# R7KA8D2AD register map
Vendor: Renesas Electronics Corporation; Series: RA8; File version: 1.10.02
CPU: CM85 r0p2, little endian, MPU, FPU, VTOR, 4 interrupt priority bits, 96 interrupts
Registers are 32-bit, read-write, reset 0x0 unless marked. A register's access mark holds for its fields unless they carry their own. Offsets are from the block's base; [hi:lo] are bit positions; {n}, {i} and the like mark numbered series; 'fields as' and 'values as' point back to an identical list.

## MRAM_NS — MS_NS System Register area
Base 0x5013C000
0x00 MRCPFB 8-bit — Code MRAM Prefetch Buffer Enable Register
  [0] MPFBEN — Code MRAM Prefetch Buffer Enable
    0=Prefetch buffer disable; 1=Prefetch buffer enable
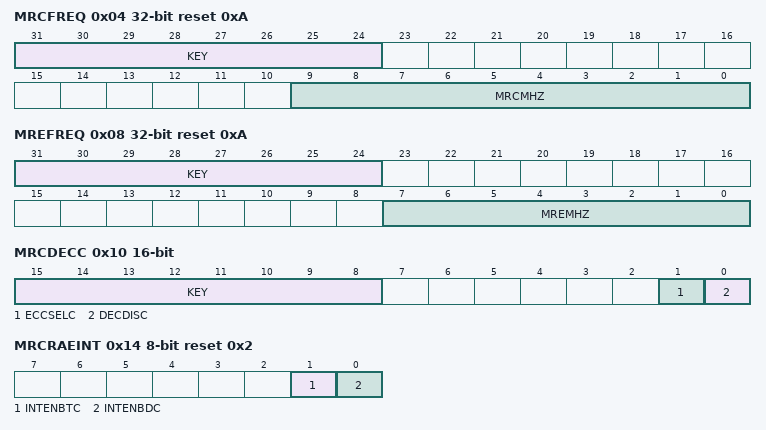
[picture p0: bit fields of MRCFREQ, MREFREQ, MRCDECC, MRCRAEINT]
0x04 MRCFREQ reset 0xA — Code MRAM Frequency Notifications Register
  [31:24] KEY — Key Code
  [9:0] MRCMHZ — Code MRAM Frequency Notifications
0x08 MREFREQ reset 0xA — Extra MRAM Frequency Notifications Register
  [31:24] KEY
  [7:0] MREMHZ — Extra MRAM Frequency Notifications
0x10 MRCDECC 16-bit — Code MRAM ECC Decoder Control Register
  [15:8] KEY — Key Code
  [1] ECCSELC — Code MRAM ECC Bits Select
    0=ECC bits unselect; 1=ECC bits select
  [0] DECDISC — Code MRAM ECC Decoder Disable
    0=ECC decoder enable; 1=ECC decoder disable
0x14 MRCRAEINT 8-bit reset 0x2 — Code MRAM Read Access Error Interrupt Enable Register
  [1] INTENBTC — Code MRAM TED Error Interrupt Enable
    0=Generation of an MRAM_MRCRD interrupt request is disabled when MRCRAES.TEDERRC is set to 1; 1=Generation of an MRAM_MRCRD interrupt request is enabled when MRCRAES.TEDERRC is set to 1
  [0] INTENBDC — Code MRAM DEC Error Interrupt Enable
    0=Generation of an MRAM_MRCRD interrupt request is disabled when MRCRAES.DECERRC is set to 1; 1=Generation of an MRAM_MRCRD interrupt request is enabled when MRCRAES.DECERRC is set to 1
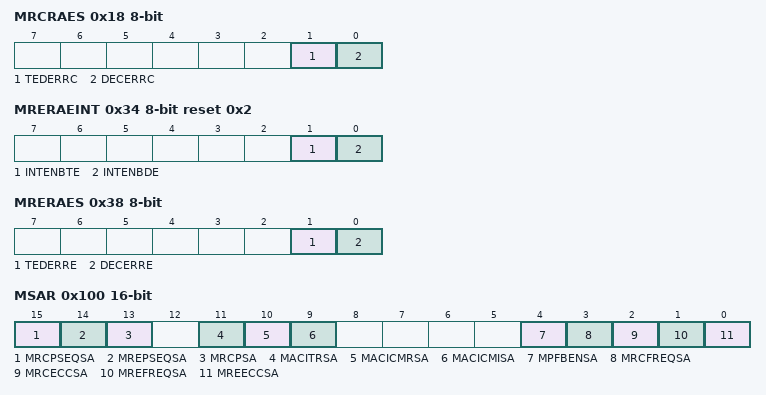
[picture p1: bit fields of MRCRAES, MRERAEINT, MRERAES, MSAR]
0x18 MRCRAES 8-bit — Code MRAM Read Access Error Status Register
  [1] TEDERRC — Code MRAM TED Error Detected
    0=TED error undetected; 1=TED error detected
  [0] DECERRC — Code MRAM DEC Error Detected
    0=DEC error undetected; 1=DEC error detected
0x1C MRCRTEA ro — Code MRAM TED Error Address Register
  [31:5] MRCRTEA — Code MRAM Read Access TED Error Address
0x20 MRCRDEA ro — Code MRAM DEC Error Address Register
  [31:5] MRCRDEA — Code MRAM Read Access DEC Error Address
0x34 MRERAEINT 8-bit reset 0x2 — Extra MRAM Read Access Error Interrupt Enable Register
  [1] INTENBTE — Code MRAM TED Error Interrupt Enable
    0=Generation of an MRAM_MRERD interrupt request is disabled when MERAES.TEDERRE is set to 1; 1=Generation of an MRAM_MRERD interrupt request is enabled when MERAES.TEDERRE is set to 1
  [0] INTENBDE — Code MRAM DEC Error Interrupt Enable
    0=Generation of an MRAM_MRERD interrupt request is disabled when MERAES.DECERRE is set to 1; 1=Generation of an MRAM_MRERD interrupt request is enabled when MERAES.DECERRE is set to 1
0x38 MRERAES 8-bit — Extra MRAM Read Access Error Status Register
  [1] TEDERRE — Extra MRAM TED Error Detected
    0=TED error undetected; 1=TED error detected
  [0] DECERRE — Extra MRAM DEC Error Detected
    0=DEC error undetected; 1=DEC error detected
0x3C MRERTEA ro — Extra MRAM TED Error Address Register
  [31:4] MRERTEA — Extra MRAM Read Access TED Error Address
0x40 MRERDEA ro — Extra MRAM DEC Error Address Register
  [31:4] MRERDEA — Extra MRAM Read Access DEC Error Address
0x100 MSAR 16-bit — MRAM Security Attribution Register
  [all] fields
    0=Secure; 1=Non-Secure
  [15] MRCPSEQSA — CPSEQ Area Register Security Attribution
  [14] MREPSEQSA — EPSEQ Area Register Security Attribution
  [13] MRCPSA — Code MRAM Program Register Security Attribution
  [11] MACITRSA — MACI Transfer Security Attribution
  [10] MACICMRSA — MACI Command Registers Security Attribution
  [9] MACICMISA — MACI command Issuing Security Attribution
  [4] MPFBENSA — MRCPFB Register Security Attribution
  [3] MRCFREQSA — MRCFREQ Register Security Attribution
  [2] MRCECCSA — Code MRAM ECC Register Security Attribution
  [1] MREFREQSA — MREFREQ Register Security Attribution
  [0] MREECCSA — Extra MRAM ECC Register Security Attribution
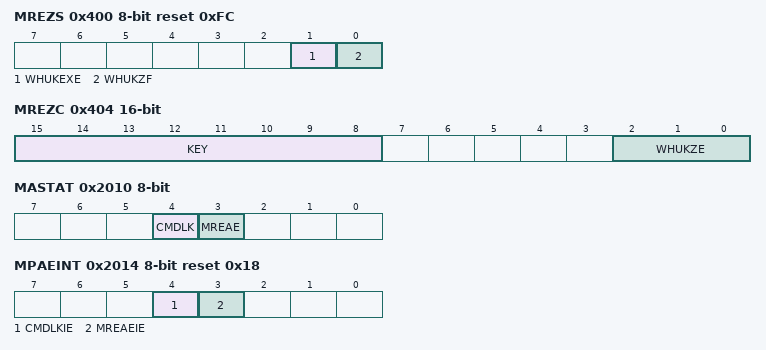
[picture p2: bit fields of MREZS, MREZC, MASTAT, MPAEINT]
0x400 MREZS 8-bit ro reset 0xFC (reset mask 0xFE) — Extra MRAM Zeroization Status Register
  [1] WHUKEXE — W-HUK Zeroization Executing Status
    0=W-HUK zeroization is not executing; 1=W-HUK zeroization is executing
  [0] WHUKZF — W-HUK Zero Flag Status
    0=W-HUK is zeroized; 1=W-HUK is not zeroized
0x404 MREZC 16-bit — Extra MRAM Zeroization Control Register
  [15:8] KEY — Key Code
  [2:0] WHUKZE — W-HUK Zeroization Execute
    0bxx0=W-HUK zeroization not executes; 7=W-HUK zeroization executes
0x2010 MASTAT 8-bit — Extra MRAM Access Status Register
  [4] CMDLK ro — Command Lock Flag
    0=The MRAM sequencer is not in the command-locked state; 1=The MRAM sequencer is in the command-locked state
  [3] MREAE — Extra MRAM Access Violation Flag
    0=No extra MRAM access violation has occurred; 1=An extra MRAM access violation has occurred
0x2014 MPAEINT 8-bit reset 0x18 — Extra MRAM Access Error Interrupt Enable Register
  [4] CMDLKIE — Command Lock Interrupt Enable
    0=Generation of an MRAM_MREPR interrupt request is disabled when MASTAT.CMDLK is set to 1; 1=Generation of an MRAM_MREPR interrupt request is enabled when MASTAT.CMDLK is set to 1
  [3] MREAEIE — Extra MRAM Access Violation Interrupt Enable
    0=Generation of an MRAM_MREPR interrupt request is disabled when MASTAT.MREAE is set to 1; 1=Generation of an MRAM_MREPR interrupt request is enabled when MASTAT.MREAE is set to 1
0x2018 MRDYIE 8-bit — Extra MRAM Ready Interrupt Enable Register
  [0] MRDYIE — Extra MRAM Ready Interrupt Enable
    0=Generation of an MRAM_ENDOFPE interrupt request is disabled; 1=Generation of an MRAM_ENDOFPE interrupt request is enabled
0x2030 MSADDR — MACI Command Start Address Register
  [31:0] MSADDR — Start Address for MACI Command Processing
0x2048 MCNTSELR 8-bit — MRAM Counter Select Register
  [2:0] CNTSEL — Counter select
    0=Anti-rollback counter is not selected; 1=ARC_SEC is selected. Counter size is 64 bits.; 2=ARC_OEMBL is selected. Counter size is 64 bits.; 3=Anti-rollback counter is not selected; 0b1xx=ARC_NSEC is selected. Counter configuration is 64 or 256 bits. See , , and for details of the counter select condition.
{0x204C+4i} MCNTDTR{i} (i=0..1) ro — MRAM Counter Data Register (n = 0, 1)
  [31:0] CNTRDAT — Counter Read Data
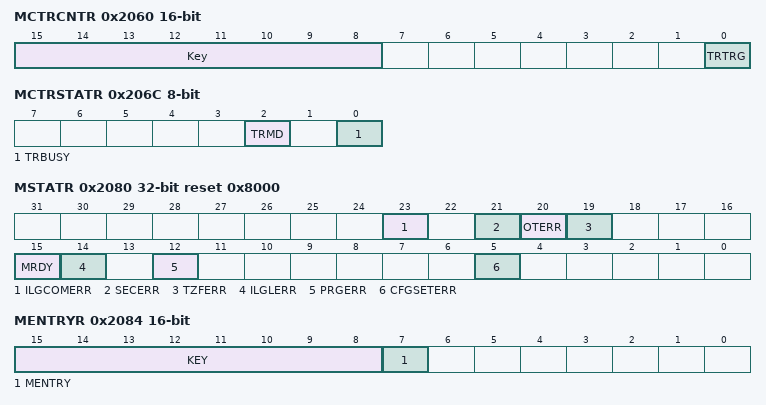
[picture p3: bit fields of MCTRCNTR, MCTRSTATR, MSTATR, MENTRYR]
0x2060 MCTRCNTR 16-bit — MRAM Configuration Update Transfer Control Register
  [15:8] Key — Key code
  [0] TRTRG — Transfer Start Trigger
    0=Configuration update transfer processing does not start; 1=Configuration update transfer processing starts
0x2064 MCTRLSR 8-bit — MRAM Configuration Update Transfer List Select Register
  [2:0] TRLIST — Configuration Update Transfer List
    1=Transfer list 1 is selected; other=Others (Transfer list 1 is not selected)
0x206C MCTRSTATR 8-bit ro — MRAM Configuration Update Transfer Status Register
  [2] TRMD — Transfer Mode Setting Status
    0=MENTRYR register is a data transferable setting; 1=MENTRYR register is not a data transferable setting
  [0] TRBUSY — Transfer Busy Status
    0=Configuration update transfer is not processing; 1=Configuration update transfer is processing
0x2080 MSTATR ro reset 0x8000 — Extra MRAM Status Register
  [23] ILGCOMERR — Illegal Command Error
    0=An illegal MACI command error has not been detected; 1=An illegal MACI command error has been detected
  [21] SECERR — Security Error
    0=A write protection error against MSUASMON.FSPR bit has not been detected; 1=A write protection error against MSUASMON.FSPR bit has been detected
  [20] OTERR — Other Error
    0=An error has not been detected; 1=An error has been detected
  [19] TZFERR — TrustZone Filter Error
    0=A TrustZone filter error has not been detected; 1=A TrustZone filter error has been detected
  [15] MRDY — Extra MRAM Ready Flag
    0=Program, Configuration set, Increment Counter, or Read Counter command processing is in progress; 1=None of the above is in progress
  [14] ILGLERR — Illegal Command Error Flag
    0=The extra MRAM sequencer has not detected an illegal MACI command or illegal extra MRAM access; 1=The extra MRAM sequencer has detected an illegal MACI command or illegal extra MRAM access
  [12] PRGERR — Programming Error Flag
    0=Programming has been completed successfully; 1=An error has occurred during programming
  [5] CFGSETERR — Configuration Set Error Flag
    0=Configuration set has been completed successfully; 1=An error has occurred during configuration set
0x2084 MENTRYR 16-bit — Extra MRAM Program Mode Entry Register
  [15:8] KEY
  [7] MENTRY — Extra MRAM Program Mode Entry
    0=Extra MRAM is in read mode; 1=Extra MRAM is in program mode
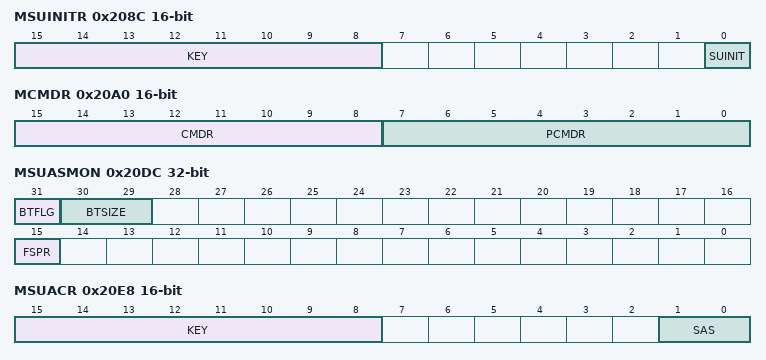
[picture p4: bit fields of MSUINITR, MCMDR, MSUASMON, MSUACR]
0x208C MSUINITR 16-bit — Extra MRAM Sequencer Setup Initialization Register
  [15:8] KEY — Key Code
  [0] SUINIT — Setup Initialization
    0=The MSADDR, MENTRYR, and MCNTSELR extra MRAM sequencer setup registers keep their current values; 1=The MSADDR, MENTRYR, and MCNTSELR extra MRAM sequencer setup registers are initialized
0x20A0 MCMDR 16-bit ro — MACI Command Register
  [15:8] CMDR — Command Flag
  [7:0] PCMDR — Pre-command Flag
0x20DC MSUASMON ro (reset mask 0x1FFF7FFF) — MRAM Startup Area Select Monitor Register
  [31] BTFLG — Flag of startup area select for boot swap
    0=The startup area is the alternate block (block 1); 1=The startup area is the default block (block 0)
  [30:29] BTSIZE — Size of startup area select for boot swap
    1=Startup area size is set to 32 KB; 2=Startup area size is set to 16 KB; 3=Startup area size is set to 8 KB
  [15] FSPR — Protection flag of programming to set boot flag and startup area control
    0=Protected state; 1=Non-protected state
0x20E8 MSUACR 16-bit — MRAM Startup Area Control Register
  [15:8] KEY — Key Code
  [1:0] SAS — Startup Area Select
    0b0x=Startup area is selected by BTFLG bit; 2=Startup area is temporarily switched to the default area; 3=Startup area is temporarily switched to the alternate area
0x2800 MRPSC 8-bit — MRAM Program Speed Control Register
  [0] MHSPEN — MRAM High-Speed Program Mode Enable
    0=Normal program mode; 1=High-speed program mode
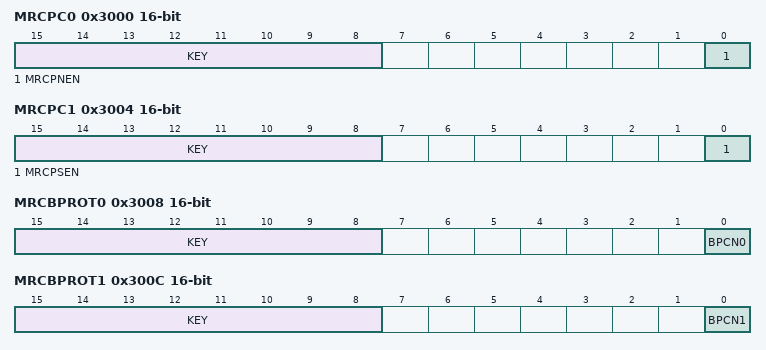
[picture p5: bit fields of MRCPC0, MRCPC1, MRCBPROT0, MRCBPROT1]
0x3000 MRCPC0 16-bit — Code MRAM Program Control Register
  [15:8] KEY — Key Code
  [0] MRCPNEN — Code MRAM Program Enable for Non-secure
    0=Code MRAM non-secure aliases are not programmable; 1=Code MRAM non-secure aliases are programmable
0x3004 MRCPC1 16-bit — Code MRAM Program Control Register for Secure
  [15:8] KEY — Key Code
  [0] MRCPSEN — Code MRAM Program Enable for Secure
    0=Code MRAM secure aliases are not programmable; 1=Code MRAM secure aliases are programmable
0x3008 MRCBPROT0 16-bit — Code MRAM Block Protection Register
  [15:8] KEY — Key Code
  [0] BPCN0 — Code MRAM Block Protection Cancel for Non-secure
    0=Code MRAM block protection is enabled; 1=Code MRAM block protection is disabled
0x300C MRCBPROT1 16-bit — Code MRAM Block Protection Register for Secure
  [15:8] KEY — Key Code
  [0] BPCN1 — Code MRAM Block Protection Cancel for Secure
    values as MRCBPROT0.BPCN0
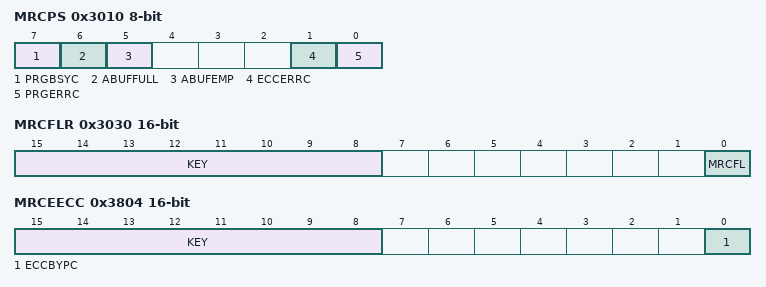
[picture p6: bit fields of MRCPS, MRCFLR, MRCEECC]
0x3010 MRCPS 8-bit — Code MRAM Program Status Register
  [7] PRGBSYC ro — Code MRAM Program Busy
    0=Code MRAM is not in program status; 1=Code MRAM is in program status
  [6] ABUFFULL ro — Address Buffer Full
    0=Address buffer is not full, and code MRAM write transaction is acceptable; 1=Address buffer is full, and code MRAM write transaction is not acceptable
  [5] ABUFEMP ro — Address Buffer Empty
    0=Address buffer is not empty, and code MRAM write data can flush; 1=Address buffer is empty, and code MRAM write data cannot flush
  [1] ECCERRC — ECC Error
    values as MSTATR.PRGERR
  [0] PRGERRC — Programming Error
    values as MSTATR.PRGERR
0x3014 MRCPAEINT 8-bit — Code MRAM Program Access Error Interrupt Enable Register
  [7] MRCAEIE — Code MRAM Program Access Error Interrupt Enable
    0=Generation of an MRAM_MRCPR interrupt request is disabled when the ECCERRC or PRGERRC bits are 1; 1=Generation of an MRAM_MRCPR interrupt request is enabled when the ECCERRC or PRGERRC bits are 1
0x3018 MRCPEA ro — Code MRAM Program Error Address Register
  [31:5] MCPEA — Code MRAM Program Error Address
0x3030 MRCFLR 16-bit — Code MRAM Flush Register
  [15:8] KEY — Key Code
  [0] MRCFL — Flush Write Data Buffer for Code MRAM
    0=Not execute to flush program data buffer; 1=Execute to flush program data buffer
0x3804 MRCEECC 16-bit — Code MRAM ECC Encoder Control Register
  [15:8] KEY — Key Code
  [0] ECCBYPC — Code MRAM ECC Encoder Outputs Bypass Enable
    0=ECC encoder output is programmed to the ECC bits of the code MRAM; 1=Bits [144:128] and bits [16:0] of written data are programmed to the ECC bits of the code MRAM
